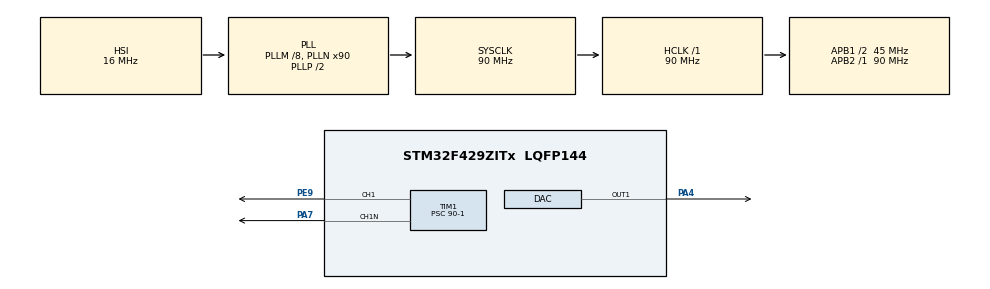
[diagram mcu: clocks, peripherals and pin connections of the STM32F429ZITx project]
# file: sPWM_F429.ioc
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DAC.DAC_Trigger=DAC_TRIGGER_T2_TRGO
Dma.DAC1.1.Direction=DMA_MEMORY_TO_PERIPH
Dma.DAC1.1.FIFOMode=DMA_FIFOMODE_DISABLE
Dma.DAC1.1.Instance=DMA1_Stream5
Dma.DAC1.1.MemDataAlignment=DMA_MDATAALIGN_WORD
Dma.DAC1.1.MemInc=DMA_MINC_ENABLE
Dma.DAC1.1.Mode=DMA_CIRCULAR
Dma.DAC1.1.PeriphDataAlignment=DMA_PDATAALIGN_WORD
Dma.DAC1.1.PeriphInc=DMA_PINC_DISABLE
Dma.DAC1.1.Priority=DMA_PRIORITY_LOW
Dma.Request0=TIM1_CH1
Dma.Request1=DAC1
Dma.TIM1_CH1.0.Direction=DMA_MEMORY_TO_PERIPH
Dma.TIM1_CH1.0.FIFOMode=DMA_FIFOMODE_DISABLE
Dma.TIM1_CH1.0.Instance=DMA2_Stream1
Dma.TIM1_CH1.0.MemDataAlignment=DMA_MDATAALIGN_WORD
Dma.TIM1_CH1.0.MemInc=DMA_MINC_ENABLE
Dma.TIM1_CH1.0.Mode=DMA_CIRCULAR
Dma.TIM1_CH1.0.PeriphDataAlignment=DMA_PDATAALIGN_WORD
Dma.TIM1_CH1.0.PeriphInc=DMA_PINC_DISABLE
Dma.TIM1_CH1.0.Priority=DMA_PRIORITY_LOW
Mcu.Family=STM32F4
Mcu.Name=STM32F429ZITx
Mcu.Package=LQFP144
NVIC.DMA1_Stream5_IRQn=true\:0\:0\:false\:false\:true\:false\:true\:true
NVIC.DMA2_Stream1_IRQn=true\:0\:0\:false\:false\:true\:false\:true\:true
NVIC.PriorityGroup=NVIC_PRIORITYGROUP_4
PA13.Mode=Serial_Wire
PA13.Signal=SYS_JTMS-SWDIO
PA14.Mode=Serial_Wire
PA14.Signal=SYS_JTCK-SWCLK
PA4.Signal=COMP_DAC1_group
PA7.Mode=PWM Generation1 CH1 CH1N
PA7.Signal=TIM1_CH1N
PE9.Signal=S_TIM1_CH1
ProjectManager.HeapSize=0x200
ProjectManager.StackSize=0x400
ProjectManager.TargetToolchain=STM32CubeIDE
RCC.48MHZClocksFreq_Value=45000000
RCC.AHBFreq_Value=90000000
RCC.APB1CLKDivider=RCC_HCLK_DIV2
RCC.APB1Freq_Value=45000000
RCC.APB1TimFreq_Value=90000000
RCC.APB2Freq_Value=90000000
RCC.APB2TimFreq_Value=90000000
RCC.CortexFreq_Value=90000000
RCC.HCLKFreq_Value=90000000
RCC.HSE_VALUE=25000000
RCC.HSI_VALUE=16000000
RCC.LSE_VALUE=32768
RCC.PLLM=8
RCC.PLLN=90
RCC.SYSCLKFreq_VALUE=90000000
RCC.SYSCLKSource=RCC_SYSCLKSOURCE_PLLCLK
RCC.VCOOutputFreq_Value=180000000
SH.COMP_DAC1_group.0=DAC_OUT1,DAC_OUT1
SH.S_TIM1_CH1.0=TIM1_CH1,PWM Generation1 CH1 CH1N
TIM1.Channel-PWM\ Generation1\ CH1\ CH1N=TIM_CHANNEL_1
TIM1.CounterMode=TIM_COUNTERMODE_CENTERALIGNED2
TIM1.OCMode_PWM-PWM\ Generation1\ CH1\ CH1N=TIM_OCMODE_PWM2
TIM1.Period=4196-1
TIM1.Prescaler=90-1
TIM2.Period=9000-1
TIM2.TIM_MasterOutputTrigger=TIM_TRGO_UPDATE
VP_TIM1_VS_ClockSourceINT.Mode=Internal
VP_TIM2_VS_ClockSourceINT.Mode=Internal
board=custom

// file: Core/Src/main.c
/* USER CODE BEGIN Header */
/**
  ******************************************************************************
  * @file           : main.c
  * @brief          : Main program body
  ******************************************************************************
  * @attention
  *
  * Copyright (c) 2022 STMicroelectronics.
  * All rights reserved.
  *
  * This software is licensed under terms that can be found in the LICENSE file
  * in the root directory of this software component.
  * If no LICENSE file comes with this software, it is provided AS-IS.
  *
  ******************************************************************************
  */
/* USER CODE END Header */
#include "main.h"

/* USER CODE BEGIN Includes */
#include <stdio.h>
#include <math.h>
/* USER CODE END Includes */

 DAC_HandleTypeDef hdac;
DMA_HandleTypeDef hdma_dac1;

TIM_HandleTypeDef htim1;
TIM_HandleTypeDef htim2;
DMA_HandleTypeDef hdma_tim1_ch1;

/* USER CODE BEGIN PV */
#define NS  200
uint32_t Wave_LUT[NS] = {2048, 2112, 2177, 2241, 2305, 2369, 2433, 2496, 2559, 2622, 2683, 2744, 2805, 2865, 2923,
		2981, 3038, 3094, 3150, 3203, 3256, 3308, 3358, 3407, 3455, 3501, 3546, 3589, 3631, 3671,
		3710, 3747, 3782, 3815, 3847, 3877, 3905, 3931, 3956, 3978, 3999, 4017, 4034, 4049, 4061,
		4072, 4081, 4087, 4092, 4094, 4095, 4093, 4090, 4084, 4077, 4067, 4055, 4042, 4026, 4008,
		3989, 3967, 3944, 3918, 3891, 3862, 3831, 3799, 3764, 3728, 3691, 3651, 3610, 3568, 3524,
		3478, 3431, 3383, 3333, 3282, 3230, 3177, 3122, 3067, 3010, 2952, 2894, 2835, 2775, 2714,
		2652, 2590, 2528, 2465, 2401, 2337, 2273, 2209, 2144, 2080, 2015, 1951, 1886, 1822, 1758,
		1694, 1630, 1567, 1505, 1443, 1381, 1320, 1260, 1201, 1143, 1085, 1028, 973, 918, 865,
		813, 762, 712, 664, 617, 571, 527, 485, 444, 404, 367, 331, 296, 264, 233,
		204, 177, 151, 128, 106, 87, 69, 53, 40, 28, 18, 11, 5, 2, 0,
		1, 3, 8, 14, 23, 34, 46, 61, 78, 96, 117, 139, 164, 190, 218,
		248, 280, 313, 348, 385, 424, 464, 506, 549, 594, 640, 688, 737, 787, 839,
		892, 945, 1001, 1057, 1114, 1172, 1230, 1290, 1351, 1412, 1473, 1536, 1599, 1662, 1726,
		1790, 1854, 1918, 1983, 2047};

/* USER CODE END PV */

void SystemClock_Config(void);
static void MX_GPIO_Init(void);
static void MX_DMA_Init(void);
static void MX_TIM1_Init(void);
static void MX_DAC_Init(void);
static void MX_TIM2_Init(void);

int main(void)
{

  /* MCU Configuration--------------------------------------------------------*/

  /* Reset of all peripherals, Initializes the Flash interface and the Systick. */
  HAL_Init();

  /* Configure the system clock */
  SystemClock_Config();

  /* Initialize all configured peripherals */
  MX_GPIO_Init();
  MX_DMA_Init();
  MX_TIM1_Init();
  MX_DAC_Init();
  MX_TIM2_Init();
  /* USER CODE BEGIN 2 */

  HAL_TIMEx_PWMN_Start(&htim1, TIM_CHANNEL_1);
  HAL_TIM_PWM_Start_DMA(&htim1, TIM_CHANNEL_1, (uint32_t*)Wave_LUT, 200);

  HAL_DAC_Start_DMA(&hdac, DAC_CHANNEL_1, Wave_LUT, 200, DAC_ALIGN_12B_R);
  HAL_TIM_Base_Start(&htim2);
  HAL_Delay(500);

  /* USER CODE END 2 */

  /* Infinite loop */
  while (1)
  {

  }
}

void SystemClock_Config(void)
{
  RCC_OscInitTypeDef RCC_OscInitStruct = {0};
  RCC_ClkInitTypeDef RCC_ClkInitStruct = {0};

  /** Configure the main internal regulator output voltage
  */
  __HAL_RCC_PWR_CLK_ENABLE();
  __HAL_PWR_VOLTAGESCALING_CONFIG(PWR_REGULATOR_VOLTAGE_SCALE3);

  /** Initializes the RCC Oscillators according to the specified parameters
  * in the RCC_OscInitTypeDef structure.
  */
  RCC_OscInitStruct.OscillatorType = RCC_OSCILLATORTYPE_HSI;
  RCC_OscInitStruct.HSIState = RCC_HSI_ON;
  RCC_OscInitStruct.HSICalibrationValue = RCC_HSICALIBRATION_DEFAULT;
  RCC_OscInitStruct.PLL.PLLState = RCC_PLL_ON;
  RCC_OscInitStruct.PLL.PLLSource = RCC_PLLSOURCE_HSI;
  RCC_OscInitStruct.PLL.PLLM = 8;
  RCC_OscInitStruct.PLL.PLLN = 90;
  RCC_OscInitStruct.PLL.PLLP = RCC_PLLP_DIV2;
  RCC_OscInitStruct.PLL.PLLQ = 4;
  if (HAL_RCC_OscConfig(&RCC_OscInitStruct) != HAL_OK)
  {
    Error_Handler();
  }

  /** Activate the Over-Drive mode
  */
  if (HAL_PWREx_EnableOverDrive() != HAL_OK)
  {
    Error_Handler();
  }

  /** Initializes the CPU, AHB and APB buses clocks
  */
  RCC_ClkInitStruct.ClockType = RCC_CLOCKTYPE_HCLK|RCC_CLOCKTYPE_SYSCLK
                              |RCC_CLOCKTYPE_PCLK1|RCC_CLOCKTYPE_PCLK2;
  RCC_ClkInitStruct.SYSCLKSource = RCC_SYSCLKSOURCE_PLLCLK;
  RCC_ClkInitStruct.AHBCLKDivider = RCC_SYSCLK_DIV1;
  RCC_ClkInitStruct.APB1CLKDivider = RCC_HCLK_DIV2;
  RCC_ClkInitStruct.APB2CLKDivider = RCC_HCLK_DIV1;

  if (HAL_RCC_ClockConfig(&RCC_ClkInitStruct, FLASH_LATENCY_2) != HAL_OK)
  {
    Error_Handler();
  }
}

static void MX_DAC_Init(void)
{

  DAC_ChannelConfTypeDef sConfig = {0};

  /** DAC Initialization
  */
  hdac.Instance = DAC;
  if (HAL_DAC_Init(&hdac) != HAL_OK)
  {
    Error_Handler();
  }

  /** DAC channel OUT1 config
  */
  sConfig.DAC_Trigger = DAC_TRIGGER_T2_TRGO;
  sConfig.DAC_OutputBuffer = DAC_OUTPUTBUFFER_ENABLE;
  if (HAL_DAC_ConfigChannel(&hdac, &sConfig, DAC_CHANNEL_1) != HAL_OK)
  {
    Error_Handler();
  }

}

static void MX_TIM1_Init(void)
{

  TIM_ClockConfigTypeDef sClockSourceConfig = {0};
  TIM_MasterConfigTypeDef sMasterConfig = {0};
  TIM_OC_InitTypeDef sConfigOC = {0};
  TIM_BreakDeadTimeConfigTypeDef sBreakDeadTimeConfig = {0};

  htim1.Instance = TIM1;
  htim1.Init.Prescaler = 90-1;
  htim1.Init.CounterMode = TIM_COUNTERMODE_CENTERALIGNED2;
  htim1.Init.Period = 4196-1;
  htim1.Init.ClockDivision = TIM_CLOCKDIVISION_DIV1;
  htim1.Init.RepetitionCounter = 0;
  htim1.Init.AutoReloadPreload = TIM_AUTORELOAD_PRELOAD_DISABLE;
  if (HAL_TIM_Base_Init(&htim1) != HAL_OK)
  {
    Error_Handler();
  }
  sClockSourceConfig.ClockSource = TIM_CLOCKSOURCE_INTERNAL;
  if (HAL_TIM_ConfigClockSource(&htim1, &sClockSourceConfig) != HAL_OK)
  {
    Error_Handler();
  }
  if (HAL_TIM_PWM_Init(&htim1) != HAL_OK)
  {
    Error_Handler();
  }
  sMasterConfig.MasterOutputTrigger = TIM_TRGO_RESET;
  sMasterConfig.MasterSlaveMode = TIM_MASTERSLAVEMODE_DISABLE;
  if (HAL_TIMEx_MasterConfigSynchronization(&htim1, &sMasterConfig) != HAL_OK)
  {
    Error_Handler();
  }
  sConfigOC.OCMode = TIM_OCMODE_PWM2;
  sConfigOC.Pulse = 0;
  sConfigOC.OCPolarity = TIM_OCPOLARITY_HIGH;
  sConfigOC.OCNPolarity = TIM_OCNPOLARITY_HIGH;
  sConfigOC.OCFastMode = TIM_OCFAST_DISABLE;
  sConfigOC.OCIdleState = TIM_OCIDLESTATE_RESET;
  sConfigOC.OCNIdleState = TIM_OCNIDLESTATE_RESET;
  if (HAL_TIM_PWM_ConfigChannel(&htim1, &sConfigOC, TIM_CHANNEL_1) != HAL_OK)
  {
    Error_Handler();
  }
  sBreakDeadTimeConfig.OffStateRunMode = TIM_OSSR_DISABLE;
  sBreakDeadTimeConfig.OffStateIDLEMode = TIM_OSSI_DISABLE;
  sBreakDeadTimeConfig.LockLevel = TIM_LOCKLEVEL_OFF;
  sBreakDeadTimeConfig.DeadTime = 0;
  sBreakDeadTimeConfig.BreakState = TIM_BREAK_DISABLE;
  sBreakDeadTimeConfig.BreakPolarity = TIM_BREAKPOLARITY_HIGH;
  sBreakDeadTimeConfig.AutomaticOutput = TIM_AUTOMATICOUTPUT_DISABLE;
  if (HAL_TIMEx_ConfigBreakDeadTime(&htim1, &sBreakDeadTimeConfig) != HAL_OK)
  {
    Error_Handler();
  }
  HAL_TIM_MspPostInit(&htim1);

}

static void MX_TIM2_Init(void)
{

  TIM_ClockConfigTypeDef sClockSourceConfig = {0};
  TIM_MasterConfigTypeDef sMasterConfig = {0};

  htim2.Instance = TIM2;
  htim2.Init.Prescaler = 0;
  htim2.Init.CounterMode = TIM_COUNTERMODE_UP;
  htim2.Init.Period = 9000-1;
  htim2.Init.ClockDivision = TIM_CLOCKDIVISION_DIV1;
  htim2.Init.AutoReloadPreload = TIM_AUTORELOAD_PRELOAD_DISABLE;
  if (HAL_TIM_Base_Init(&htim2) != HAL_OK)
  {
    Error_Handler();
  }
  sClockSourceConfig.ClockSource = TIM_CLOCKSOURCE_INTERNAL;
  if (HAL_TIM_ConfigClockSource(&htim2, &sClockSourceConfig) != HAL_OK)
  {
    Error_Handler();
  }
  sMasterConfig.MasterOutputTrigger = TIM_TRGO_UPDATE;
  sMasterConfig.MasterSlaveMode = TIM_MASTERSLAVEMODE_DISABLE;
  if (HAL_TIMEx_MasterConfigSynchronization(&htim2, &sMasterConfig) != HAL_OK)
  {
    Error_Handler();
  }

}

static void MX_DMA_Init(void)
{

  /* DMA controller clock enable */
  __HAL_RCC_DMA2_CLK_ENABLE();
  __HAL_RCC_DMA1_CLK_ENABLE();

  /* DMA interrupt init */
  /* DMA1_Stream5_IRQn interrupt configuration */
  HAL_NVIC_SetPriority(DMA1_Stream5_IRQn, 0, 0);
  HAL_NVIC_EnableIRQ(DMA1_Stream5_IRQn);
  /* DMA2_Stream1_IRQn interrupt configuration */
  HAL_NVIC_SetPriority(DMA2_Stream1_IRQn, 0, 0);
  HAL_NVIC_EnableIRQ(DMA2_Stream1_IRQn);

}

static void MX_GPIO_Init(void)
{

  /* GPIO Ports Clock Enable */
  __HAL_RCC_GPIOA_CLK_ENABLE();
  __HAL_RCC_GPIOE_CLK_ENABLE();

}

void Error_Handler(void)
{
  __disable_irq();
  while (1)
  {
  }
}
